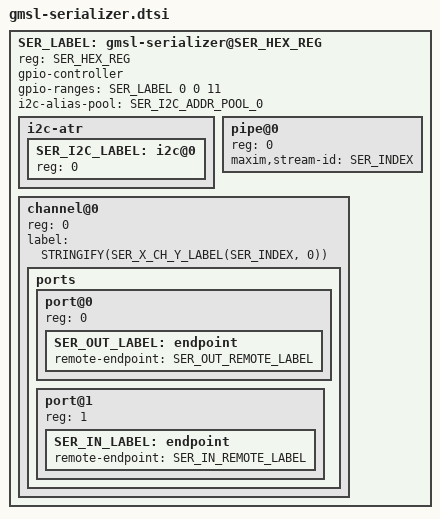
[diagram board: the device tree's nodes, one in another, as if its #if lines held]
// SPDX-License-Identifier: GPL-2.0
/*
 * Copyright (C) 2023 Analog Devices Inc.
 */

#if defined(SER_INDEX)
#define SER_LABEL SER_X_LABEL(SER_INDEX)
#define SER_I2C_LABEL CONCAT(SER_LABEL, _i2c_0)
#define SER_OUT_LABEL SER_X_CH_Y_OUT_LABEL(SER_INDEX, 0)
#define SER_IN_LABEL SER_X_CH_Y_IN_LABEL(SER_INDEX, 0)
#endif

#if defined(DES_CH_INDEX)
#define SER_OUT_REMOTE_LABEL DES_CH_Y_IN_LABEL(DES_CH_INDEX)
#endif

#if defined(CAM_INDEX)
#define SER_IN_REMOTE_LABEL CAM_X_OUT_LABEL(CAM_INDEX)
#endif

#if !defined(SER_I2C_LABEL)
#error
#endif

#if !defined(SER_COMPAT)
#error
#endif

#if !defined(SER_HEX_REG)
#error
#endif

#if !defined(SER_LABEL)
#error
#endif

#if !defined(SER_OUT_LABEL)
#error
#endif

#if !defined(SER_IN_LABEL)
#error
#endif

#if !defined(SER_OUT_REMOTE_LABEL)
#error
#endif

#if !defined(SER_IN_REMOTE_LABEL)
#error
#endif

#if !defined(SER_I2C_ADDR_POOL_0)
#error
#endif

SER_LABEL: gmsl-serializer@SER_HEX_REG {
	#address-cells = <1>;
	#size-cells = <0>;

	compatible = SER_COMPAT;
	reg = <SER_HEX_REG>;

	gpio-controller;
	#gpio-cells = <2>;
	gpio-ranges = <&SER_LABEL 0 0 11>;

	i2c-alias-pool = <SER_I2C_ADDR_POOL_0>;

	i2c-atr {
		#address-cells = <1>;
		#size-cells = <0>;

		SER_I2C_LABEL: i2c@0 {
			#address-cells = <1>;
			#size-cells = <0>;

			reg = <0>;
		};
	};

	pipe@0 {
		reg = <0>;

		maxim,stream-id = <SER_INDEX>;
	};

	channel@0 {
		reg = <0>;

		label = STRINGIFY(SER_X_CH_Y_LABEL(SER_INDEX, 0));

		ports {
			#address-cells = <1>;
			#size-cells = <0>;

			port@0 {
				reg = <0>;

				SER_OUT_LABEL: endpoint {
					remote-endpoint = <&SER_OUT_REMOTE_LABEL>;
				};
			};

			port@1 {
				reg = <1>;

				SER_IN_LABEL: endpoint {
					remote-endpoint = <&SER_IN_REMOTE_LABEL>;
				};
			};
		};
	};
};

#undef SER_COMPAT
#undef SER_HEX_REG
#undef SER_INDEX
#undef DES_CH_INDEX
#undef CAM_INDEX
#undef SER_LABEL
#undef SER_OUT_LABEL
#undef SER_IN_LABEL
#undef SER_OUT_REMOTE_LABEL
#undef SER_IN_REMOTE_LABEL
#undef SER_I2C_ADDR_POOL_0
